# nrf9120_mlm1_modem register map
Vendor: Nordic Semiconductor; Series: nrf91; File version: 1
CPU: CM4 r0p1, little endian, MPU, no FPU, 3 interrupt priority bits
Registers are 32-bit, read-write, reset 0x0 unless marked. A register's access mark holds for its fields unless they carry their own. Offsets are from the block's base; [hi:lo] are bit positions; 'fields as' and 'values as' point back to an identical list.

## SHA — SHA-1/SHA-256
Base 0x40050000
0x00 TASKS_START_GATHER wo — Start input DMA.
  [0] TASKS_START_GATHER
    1=Trigger task
0x04 TASKS_STOP_GATHER wo — Stop input DMA.
  [0] TASKS_STOP_GATHER
    1=Trigger task
0x08 TASKS_START_OPERATION wo — Start SHA-x operation depending on mode (start accepting data).
  [0] TASKS_START_OPERATION
    1=Trigger task
0x0C TASKS_FINALIZE wo — Finalize SHA calculation.
  [0] TASKS_FINALIZE
    1=Trigger task
0x10 TASKS_RESET wo — Stop all transfers and crypto operations (initialize).
  [0] TASKS_RESET
    1=Trigger task
0x100 EVENTS_GATHER_STARTED — Input DMA started.
  [0] EVENTS_GATHER_STARTED
    0=NotGenerated (Event not generated); 1=Generated (Event generated)
0x104 EVENTS_GATHER_DONE — Input DMA done.
  [0] EVENTS_GATHER_DONE
    values as EVENTS_GATHER_STARTED.EVENTS_GATHER_STARTED
0x108 EVENTS_Unused — Unused
  [0] EVENTS_Unused
    values as EVENTS_GATHER_STARTED.EVENTS_GATHER_STARTED
0x10C EVENTS_MESSAGE_READY — LENGTH == 0.
  [0] EVENTS_MESSAGE_READY
    values as EVENTS_GATHER_STARTED.EVENTS_GATHER_STARTED
0x110 EVENTS_SHA_READY — SHA calculated.
  [0] EVENTS_SHA_READY
    values as EVENTS_GATHER_STARTED.EVENTS_GATHER_STARTED
0x114 EVENTS_RESETTED — Resetted (all transfers and crypto operations stopped).
  [0] EVENTS_RESETTED
    values as EVENTS_GATHER_STARTED.EVENTS_GATHER_STARTED
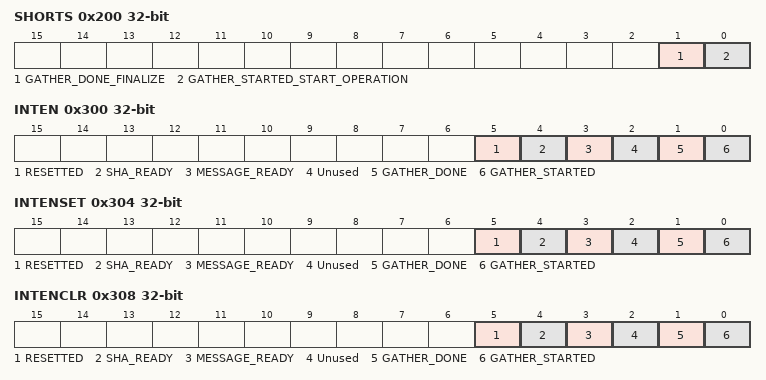
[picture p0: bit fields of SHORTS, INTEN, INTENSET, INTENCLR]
0x200 SHORTS — Shortcuts between local events and tasks
  [1] GATHER_DONE_FINALIZE — Shortcut between event GATHER_DONE and task FINALIZE
    0=Disabled (Disable shortcut); 1=Enabled (Enable shortcut)
  [0] GATHER_STARTED_START_OPERATION — Shortcut between event GATHER_STARTED and task START_OPERATION
    0=Disabled (Disable shortcut); 1=Enabled (Enable shortcut)
0x300 INTEN — Enable or disable interrupt
  [all] fields
    0=Disabled; 1=Enabled
  [5] RESETTED — Enable or disable interrupt for event RESETTED
  [4] SHA_READY — Enable or disable interrupt for event SHA_READY
  [3] MESSAGE_READY — Enable or disable interrupt for event MESSAGE_READY
  [2] Unused — Enable or disable interrupt for event Unused
  [1] GATHER_DONE — Enable or disable interrupt for event GATHER_DONE
  [0] GATHER_STARTED — Enable or disable interrupt for event GATHER_STARTED
0x304 INTENSET — Enable interrupt
  [all] fields
    on read: 0=Disabled (Read: Disabled); 1=Enabled (Read: Enabled) | on write: 1=Set (Enable)
  [5] RESETTED — Write '1' to enable interrupt for event RESETTED
  [4] SHA_READY — Write '1' to enable interrupt for event SHA_READY
  [3] MESSAGE_READY — Write '1' to enable interrupt for event MESSAGE_READY
  [2] Unused — Write '1' to enable interrupt for event Unused
  [1] GATHER_DONE — Write '1' to enable interrupt for event GATHER_DONE
  [0] GATHER_STARTED — Write '1' to enable interrupt for event GATHER_STARTED
0x308 INTENCLR — Disable interrupt
  [all] fields
    on read: 0=Disabled (Read: Disabled); 1=Enabled (Read: Enabled) | on write: 1=Clear (Disable)
  [5] RESETTED — Write '1' to disable interrupt for event RESETTED
  [4] SHA_READY — Write '1' to disable interrupt for event SHA_READY
  [3] MESSAGE_READY — Write '1' to disable interrupt for event MESSAGE_READY
  [2] Unused — Write '1' to disable interrupt for event Unused
  [1] GATHER_DONE — Write '1' to disable interrupt for event GATHER_DONE
  [0] GATHER_STARTED — Write '1' to disable interrupt for event GATHER_STARTED
0x400 LENGTH — Message length in bits.
0x404 MODE — Configuration.
  [1:0] MODE — MODE SELECTION
    0=SHA_1 (SHA-1 mode); 2=SHA_256 (SHA-256 mode)
0x600 H7 ro — Final result H7 (SHA-256), H4 (SHA-1). Updated after every 512bit block calculated.
  [31:0] Data — Data7
0x604 H6 ro — Final result H6 (SHA-256), H3 (SHA-1). Updated after every 512bit block calculated.
  [31:0] Data — Data6
0x608 H5 ro — Final result H5 (SHA-256), H2 (SHA-1). Updated after every 512bit block calculated.
  [31:0] Data — Data5
0x60C H4 ro — Final result H4 (SHA-256), H1 (SHA-1). Updated after every 512bit block calculated.
  [31:0] Data — Data4
0x610 H3 ro — Final result H3 (SHA-256), H0 (SHA-1). Updated after every 512bit block calculated.
  [31:0] Data — Data3
0x614 H2 ro — Final result H2 (SHA-256). Updated after every 512bit block calculated.
  [31:0] Data — Data2
0x618 H1 ro — Final result H1 (SHA-256). Updated after every 512bit block calculated.
  [31:0] Data — Data1
0x61C H0 ro — Final result H0 (SHA-256). Updated after every 512bit block calculated..
  [31:0] Data — Data0
0x630 H7_R ro — Final result H7_R (SHA-256), H4_R (SHA-1) in reversed byte order. Updated after every 512bit block calculated.
  [31:0] Data — Data7
0x634 H6_R ro — Final result H6_R (SHA-256), H3_R (SHA-1) in reversed byte order. Updated after every 512bit block calculated.
  [31:0] Data — Data6
0x638 H5_R ro — Final result H5_R (SHA-256), H2_R (SHA-1) in reversed byte order. Updated after every 512bit block calculated.
  [31:0] Data — Data5
0x63C H4_R ro — Final result H4_R (SHA-256), H1_R (SHA-1) in reversed byte order. Updated after every 512bit block calculated.
  [31:0] Data — Data4
0x640 H3_R ro — Final result H3_R (SHA-256), H0_R (SHA-1) in reversed byte order. Updated after every 512bit block calculated.
  [31:0] Data — Data3
0x644 H2_R ro — Final result H2_R (SHA-256) in reversed byte order. Updated after every 512bit block calculated.
  [31:0] Data — Data2
0x648 H1_R ro — Final result H1_R (SHA-256) in reversed byte order. Updated after every 512bit block calculated.
  [31:0] Data — Data1
0x64C H0_R ro — Final result H0_R (SHA-256) in reversed byte order. Updated after every 512bit block calculated..
  [31:0] Data — Data0
0x800 INJOBPTR — Input job pointer.
0x804 INJOBINDEX ro — Current input job index.
0x808 INBYTECOUNT ro — Bytes transferred in current job.
